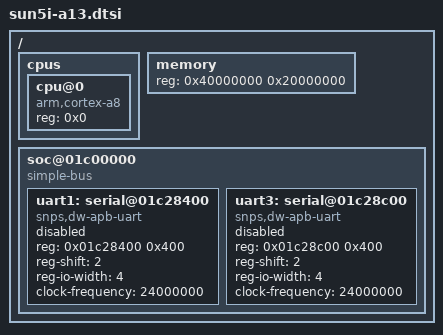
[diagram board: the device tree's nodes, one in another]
/*
 * Copyright 2014 (C) Antoine Tenart
 *
 * Antoine Tenart <antoine.tenart@free-electrons.com>
 *
 * This file is licensed under the terms of the GNU General Public
 * License version 2. This program is licensed "as is" without any
 * warranty of any kind, whether express or implied.
 */

/include/ "skeleton.dtsi"

/ {
	cpus {
		#address-cells = <1>;
		#size-cells = <0>;

		cpu@0 {
			device_type = "cpu";
			compatible = "arm,cortex-a8";
			reg = <0x0>;
		};
	};

	memory {
		reg = <0x40000000 0x20000000>;
	};

	soc@01c00000 {
		compatible = "simple-bus";
		#address-cells = <1>;
		#size-cells = <1>;
		ranges;

		uart1: serial@01c28400 {
			compatible = "snps,dw-apb-uart";
			reg = <0x01c28400 0x400>;
			reg-shift = <2>;
			reg-io-width = <4>;
			clock-frequency = <24000000>;
			status = "disabled";
		};

		uart3: serial@01c28c00 {
			compatible = "snps,dw-apb-uart";
			reg = <0x01c28c00 0x400>;
			reg-shift = <2>;
			reg-io-width = <4>;
			clock-frequency = <24000000>;
			status = "disabled";
		};
	};
};
